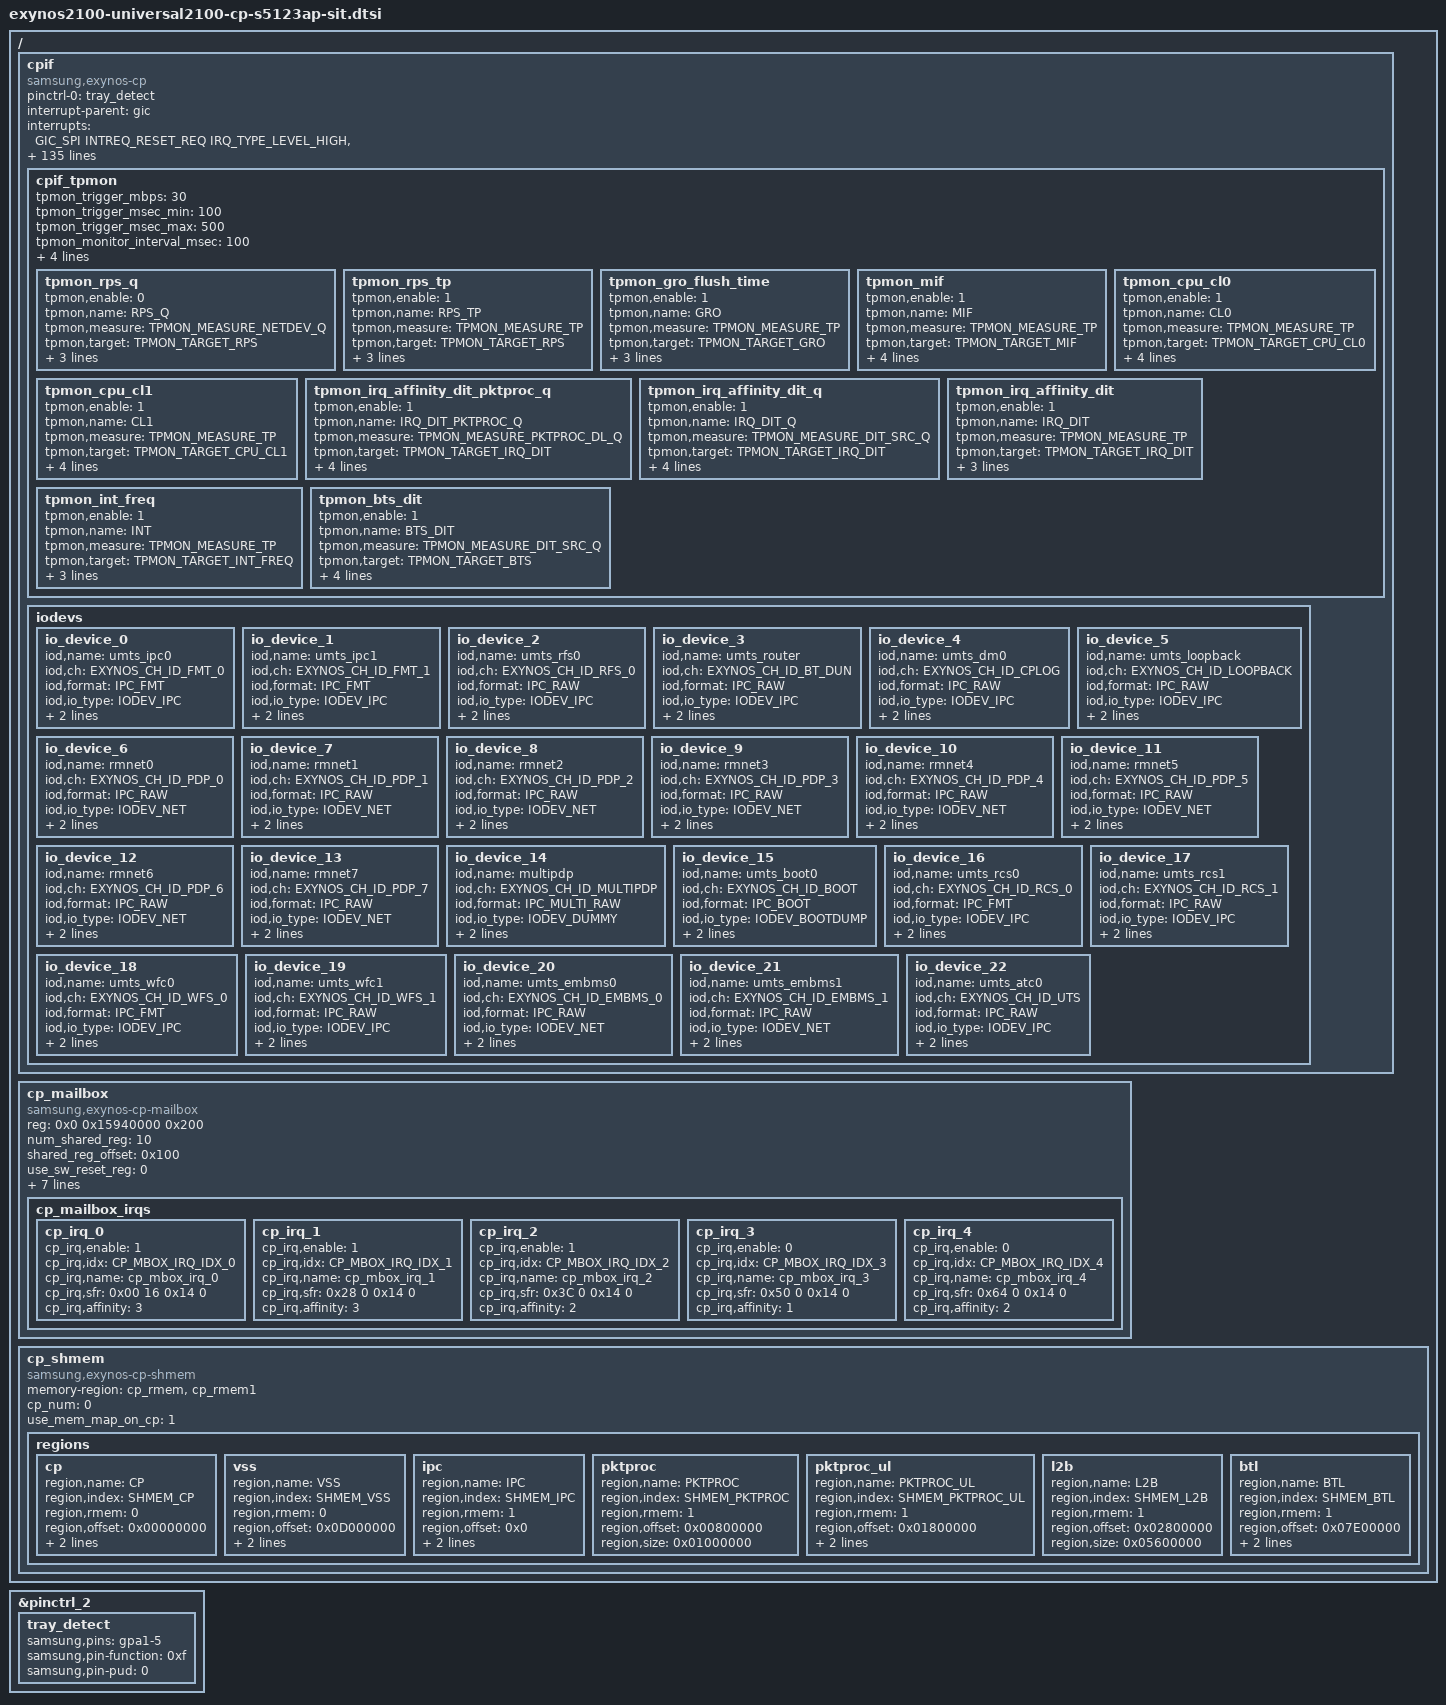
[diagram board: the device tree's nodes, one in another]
// SPDX-License-Identifier: GPL-2.0
/*
 * Samsung CP interface device tree source
 *
 * Copyright (c) 2019-2020 Samsung Electronics Co., Ltd.
 *             http://www.samsung.com
 *
 * This program is free software; you can redistribute it and/or modify
 * it under the terms of the GNU General Public License version 2 as
 * published by the Free Software Foundation.
 */

#include <dt-bindings/soc/samsung/exynos-cpif.h>
#include <dt-bindings/interrupt-controller/exynos2100.h>

/ {
	fragment@modemif {
		target-path = "/";
		__overlay__ {
			#address-cells = <2>;
			#size-cells = <1>;

			/* Modem interface information */
			cpif {
				compatible = "samsung,exynos-cp";
				status = "okay";

				pinctrl-names = "default";
				pinctrl-0 = <&tray_detect>;

				interrupt-parent = <&gic>;
				interrupts = <GIC_SPI INTREQ_RESET_REQ IRQ_TYPE_LEVEL_HIGH>,
						<GIC_SPI SFR_BUS_RDY IRQ_TYPE_LEVEL_HIGH>;
				interrupt-names = "RESET_REQ", "CP_ACTIVE";

				ap2cp_cfg_addr = <0x14020000>;

				/* */
				mif,name = "s5123ap";
				mif,cp_num = <0>;
				mif,modem_type = <SEC_S5000AP>;
				mif,protocol = <PROTOCOL_SIT>;
				mif,ipc_version = <SIPC_VER_50>;
				mif,link_type = <LINKDEV_SHMEM>;
				mif,link_name = "shmem";
				mif,link_attrs = <(LINK_ATTR_XMIT_BTDLR |
							LINK_ATTR_DUMP_ALIGNED | LINK_ATTR_BOOT_ALIGNED |
							LINK_ATTR_MEM_DUMP | LINK_ATTR_MEM_BOOT |
							LINK_ATTR_DPRAM_MAGIC)>;
				mif,interrupt_types = <INTERRUPT_MAILBOX>;
				mif,capability_check = <1>;

				/* Mailbox interrupt number from AP to CP */
				mif,int_ap2cp_msg = <0>;
				mif,int_ap2cp_wakeup = <1>;
				mif,int_ap2cp_status = <2>;
				mif,int_ap2cp_active = <3>;
				mif,int_ap2cp_lcd_status = <4>;
				mif,int_ap2cp_llc_status = <5>;
				mif,int_ap2cp_uart_noti = <15>;

				/* Mailbox interrupt number from CP to AP */
				mif,irq_cp2ap_msg = <0>;
				mif,irq_cp2ap_status = <2>;
				mif,irq_cp2ap_active = <3>;
				mif,irq_cp2ap_wakelock = <8>;
				mif,irq_cp2ap_ratmode = <9>;

				/* Malibox (CP_MBOX_IRQ_IDX_2) interrupt number from CP to AP */
				mif,mbox2_irq_cp2ap_llc_status = <5>;

				/* Legacy Buffers (FMT, RAW) */
				legacy_fmt_head_tail_offset = <0x10>;
				legacy_fmt_buffer_offset = <0x1000>;
				legacy_fmt_txq_size = <0x1000>;
				legacy_fmt_rxq_size = <0x1000>;
				legacy_raw_head_tail_offset = <0x20>;
				legacy_raw_buffer_offset = <0x3000>;
				legacy_raw_txq_size = <0x1FD000>;
				legacy_raw_rxq_size = <0x200000>;

				/*
				 * Legacy Priority Queue
				 * (available only if CONFIG_MODEM_IF_LEGACY_QOS used)
				 */
				legacy_raw_qos_head_tail_offset = <0x30>;
				legacy_raw_qos_buffer_offset = <0x400000>;
				legacy_raw_qos_txq_size = <0x100000>;
				legacy_raw_qos_rxq_size = <0x100000>;

				offset_cmsg_offset = <0x60>;
				offset_srinfo_offset = <0x64>;
				offset_clk_table_offset = <0x68>;
				offset_buff_desc_offset = <0x6C>;
				offset_capability_offset = <0x70>;

				cmsg_offset = <0xC0>;
				srinfo_offset = <0x300>;
				srinfo_size = <0x800>;
				clk_table_offset = <0x200>;
				buff_desc_offset = <0xC00>;
				capability_offset = <0xA0>;

				/* capability value */
				ap_capability_0 = <0x0>;
				ap_capability_1 = <0x0>;

				/*
				 * Control messages containing two elements
				 * <MAILBOX_SR [shared register number]>
				 * <DRAM_V1   [offset from ipc base]>
				 * <DRAM_V2   [offset from cmsg offset]>
				 */
				ap2cp_msg = <DRAM_V2 0x0>;
				cp2ap_msg = <DRAM_V2 0x4>;
				ap2cp_united_status = <DRAM_V2 0x8>;
				cp2ap_united_status = <DRAM_V2 0xC>;
				ap2cp_llc_status = <DRAM_V2 0x10>;
				cp2ap_llc_status = <DRAM_V2 0x14>;
				ap2cp_kerneltime_sec = <DRAM_V2 0x38>;
				ap2cp_kerneltime_usec = <DRAM_V2 0x3C>;

				/* Status bit info for mbx_ap2cp_united_status */
				sbi_lcd_status_mask = <0x1>;
				sbi_lcd_status_pos = <27>;
				sbi_crash_type_mask = <0xf>;
				sbi_crash_type_pos = <23>;
				sbi_ext_backtrace_mask = <0x1>;
				sbi_ext_backtrace_pos = <17>;
				sbi_uart_noti_mask = <0x1>;
				sbi_uart_noti_pos = <16>;
				sbi_ds_det_mask = <0x3>;
				sbi_ds_det_pos = <14>;
				sbi_sys_rev_mask = <0xff>;
				sbi_sys_rev_pos = <6>;
				sbi_pda_active_mask = <0x1>;
				sbi_pda_active_pos = <5>;
				sbi_ap_status_mask = <0xf>;
				sbi_ap_status_pos = <1>;

				/* Status bit info for mbx_cp2ap_united_status */
				sbi_cp_rat_mode_mask = <0x3f>;
				sbi_cp_rat_mode_pos = <26>;
				sbi_cp_evs_mode_mask = <0x1>;
				sbi_cp_evs_mode_pos = <7>;
				sbi_cp2ap_wakelock_mask = <0x1>;
				sbi_cp2ap_wakelock_pos = <6>;
				sbi_lte_active_mask = <0x1>;
				sbi_lte_active_pos = <5>;
				sbi_cp_status_mask = <0xf>;
				sbi_cp_status_pos = <1>;

				/* status bit info for ap2cp_llc_status */
				sbi_ap_llc_return_mask = <0xf>;
				sbi_ap_llc_return_pos = <9>;
				sbi_ap_llc_alloc_mask = <0x1>;
				sbi_ap_llc_alloc_pos = <8>;
				sbi_ap_llc_way_mask = <0xff>;
				sbi_ap_llc_way_pos = <0>;

				/* status bit info for cp2ap_llc_status */
				sbi_cp_llc_return_mask = <0xf>;
				sbi_cp_llc_return_pos = <9>;
				sbi_cp_llc_alloc_mask = <0x1>;
				sbi_cp_llc_alloc_pos = <8>;
				sbi_cp_llc_way_mask = <0xff>;
				sbi_cp_llc_way_pos = <0>;

				/* CP BTL (Back Trace Log) */
				cp_btl_node_name = "ramdump_memshare";

				/* Packet processor */
				pktproc_support = <1>;
				pktproc_version = <2>;

				pktproc_cp_base = <0x50800000>;
				pktproc_info_rgn_offset = <0x00000000>;
				pktproc_info_rgn_size = <0x00000100>;
				pktproc_desc_rgn_offset = <0x00000100>;
				pktproc_desc_rgn_size = <0x000FFF00>;
				pktproc_buff_rgn_offset = <0x00100000>;
				/* Size of data buffer region is defined by reserved mem size */

				pktproc_info_desc_rgn_cached = <0>;
				pktproc_buff_rgn_cached = <0>;

				pktproc_desc_mode = <1>;	/* Descriptor structure mode. 0:ringbuf mode, 1:sktbuf mode */
				pktproc_num_queue = <1>;
				pktproc_use_exclusive_irq = <1>;
				pktproc_exclusive_irq_idx = <CP_MBOX_IRQ_IDX_1 CP_MBOX_IRQ_IDX_2 CP_MBOX_IRQ_IDX_3 CP_MBOX_IRQ_IDX_4>;
				pktproc_use_buff_mng = <0>;
				pktproc_desc_num_ratio_percent = <50>;
				pktproc_use_napi = <1>;
				pktproc_use_hw_iocc = <0>;	/* H/W IO cache coherency */
				pktproc_max_packet_size = <2048>;
				pktproc_use_dedicated_baaw = <1>;
				pktproc_use_36bit_data_addr = <1>;

				/* Packet processor for UL */
				pktproc_support_ul = <1>;
				pktproc_ul_cp_base = <0x51800000>;
				pktproc_ul_info_rgn_offset = <0x00000000>;
				pktproc_ul_info_rgn_size = <0x00000100>;
				pktproc_ul_desc_rgn_offset = <0x00000100>;
				pktproc_ul_desc_rgn_size = <0x000FFF00>;
				pktproc_ul_buff_rgn_offset = <0x00100000>;
				pktproc_ul_padding_required = <1>; /* for s5123 EVT1 only */
				pktproc_ul_num_queue = <2>;
				pktproc_ul_max_packet_size = <2048>;
				pktproc_ul_info_desc_rgn_cached = <0>;
				pktproc_ul_buff_rgn_cached = <0>;
				pktproc_ul_use_hw_iocc = <0>; /* H/W IO cache coherency */

				devfreq_use_dfs_max_freq = <1>;
				devfreq_cal_id_mif = <ACPM_DVFS_MIF>;

				/* TPMON: CP throughput monitor */
				cpif_tpmon {
					tpmon_trigger_mbps = <30>;
					tpmon_trigger_msec_min = <100>;
					tpmon_trigger_msec_max = <500>;

					tpmon_monitor_interval_msec = <100>;
					tpmon_monitor_hold_msec = <3000>;
					tpmon_monitor_stop_mbps = <15>;

					tpmon_boost_hold_msec = <6000>;
					tpmon_unboost_tp_percent = <40>;

					tpmon_rps_q {
						tpmon,enable = <0>;
						tpmon,name = "RPS_Q";
						tpmon,measure = <TPMON_MEASURE_NETDEV_Q>;
						tpmon,target = <TPMON_TARGET_RPS>;
						tpmon,idx = <0>;
						tpmon,threshold = <3000>;	/* Netdev backlog queue */
						tpmon,values = <0x03 0x30>;
					};
					tpmon_rps_tp {
						tpmon,enable = <1>;
						tpmon,name = "RPS_TP";
						tpmon,measure = <TPMON_MEASURE_TP>;
						tpmon,target = <TPMON_TARGET_RPS>;
						tpmon,idx = <0>;
						tpmon,threshold = <300>;	/* Mbps */
						tpmon,values = <0x03 0x30>;
					};
					tpmon_gro_flush_time {
						tpmon,enable = <1>;
						tpmon,name = "GRO";
						tpmon,measure = <TPMON_MEASURE_TP>;
						tpmon,target = <TPMON_TARGET_GRO>;
						tpmon,idx = <0>;
						tpmon,threshold = <100 200>;	/* Mbps */
						tpmon,values = <10000 50000 100000>;
					};
					tpmon_mif {
						tpmon,enable = <1>;
						tpmon,name = "MIF";
						tpmon,measure = <TPMON_MEASURE_TP>;
						tpmon,target = <TPMON_TARGET_MIF>;
						tpmon,idx = <0>;
						tpmon,threshold = <700>;	/* Mbps */
						tpmon,values = <0 1014000>;
						tpmon,check_udp = <1>;
					};
					tpmon_cpu_cl0 {
						tpmon,enable = <1>;
						tpmon,name = "CL0";
						tpmon,measure = <TPMON_MEASURE_TP>;
						tpmon,target = <TPMON_TARGET_CPU_CL0>;
						tpmon,idx = <0>;
						tpmon,threshold = <100 300>;	/* Mbps */
						tpmon,values = <0 1066000 1274000>;
						tpmon,check_udp = <1>;
					};
					tpmon_cpu_cl1 {
						tpmon,enable = <1>;
						tpmon,name = "CL1";
						tpmon,measure = <TPMON_MEASURE_TP>;
						tpmon,target = <TPMON_TARGET_CPU_CL1>;
						tpmon,idx = <4>;
						tpmon,threshold = <500 700 1500>;	/* Mbps */
						tpmon,values = <0 832000 1248000 1560000>;
						tpmon,check_udp = <1>;
					};
					tpmon_irq_affinity_dit_pktproc_q {
						tpmon,enable = <1>;
						tpmon,name = "IRQ_DIT_PKTPROC_Q";
						tpmon,measure = <TPMON_MEASURE_PKTPROC_DL_Q>;
						tpmon,target = <TPMON_TARGET_IRQ_DIT>;
						tpmon,idx = <0>;
						tpmon,threshold = <6000>;	/* PktProc rear~fore usage */
						tpmon,values = <2 6>;
						tpmon,urgent = <1>;
					};
					tpmon_irq_affinity_dit_q {
						tpmon,enable = <1>;
						tpmon,name = "IRQ_DIT_Q";
						tpmon,measure = <TPMON_MEASURE_DIT_SRC_Q>;
						tpmon,target = <TPMON_TARGET_IRQ_DIT>;
						tpmon,idx = <0>;
						tpmon,threshold = <7000>;	/* DIT src queue */
						tpmon,values = <2 6>;
						tpmon,urgent = <1>;
					};
					tpmon_irq_affinity_dit {
						tpmon,enable = <1>;
						tpmon,name = "IRQ_DIT";
						tpmon,measure = <TPMON_MEASURE_TP>;
						tpmon,target = <TPMON_TARGET_IRQ_DIT>;
						tpmon,idx = <0>;
						tpmon,threshold = <1750>;	/* Mbps */
						tpmon,values = <2 6>;
					};
					tpmon_int_freq {
						tpmon,enable = <1>;
						tpmon,name = "INT";
						tpmon,measure = <TPMON_MEASURE_TP>;
						tpmon,target = <TPMON_TARGET_INT_FREQ>;
						tpmon,idx = <0>;
						tpmon,threshold = <1750 2750>;	/* Mbps */
						tpmon,values = <0 400000 533000>;
					};
					tpmon_bts_dit {
						tpmon,enable = <1>;
						tpmon,name = "BTS_DIT";
						tpmon,measure = <TPMON_MEASURE_DIT_SRC_Q>;
						tpmon,target = <TPMON_TARGET_BTS>;
						tpmon,idx = <0>;
						tpmon,threshold = <4000>;	/* DIT src queue */
						tpmon,values = <0 1>;
						tpmon,urgent = <1>;
					};
				}; /* end of cpif_tpmon */

				/* IO devices */
				iodevs {
					io_device_0 {
						iod,name = "umts_ipc0";
						iod,ch = <EXYNOS_CH_ID_FMT_0>;
						iod,format = <IPC_FMT>;
						iod,io_type = <IODEV_IPC>;
						iod,link_type = <LINKDEV_SHMEM>;
						iod,attrs = <(0x0)>;
					};
					io_device_1 {
						iod,name = "umts_ipc1";
						iod,ch = <EXYNOS_CH_ID_FMT_1>;
						iod,format = <IPC_FMT>;
						iod,io_type = <IODEV_IPC>;
						iod,link_type = <LINKDEV_SHMEM>;
						iod,attrs = <(0x0)>;
					};
					io_device_2 {
						iod,name = "umts_rfs0";
						iod,ch = <EXYNOS_CH_ID_RFS_0>;
						iod,format = <IPC_RAW>;
						iod,io_type = <IODEV_IPC>;
						iod,link_type = <LINKDEV_SHMEM>;
						iod,attrs = <(0x0)>;
					};
					io_device_3 {
						iod,name = "umts_router";
						iod,ch = <EXYNOS_CH_ID_BT_DUN>;
						iod,format = <IPC_RAW>;
						iod,io_type = <IODEV_IPC>;
						iod,link_type = <LINKDEV_SHMEM>;
						iod,attrs = <(0x0)>;
					};
					io_device_4 {
						iod,name = "umts_dm0";
						iod,ch = <EXYNOS_CH_ID_CPLOG>;
						iod,format = <IPC_RAW>;
						iod,io_type = <IODEV_IPC>;
						iod,link_type = <LINKDEV_SHMEM>;
						iod,attrs = <(0x0)>;
					};
					io_device_5 {
						iod,name = "umts_loopback";
						iod,ch = <EXYNOS_CH_ID_LOOPBACK>;
						iod,format = <IPC_RAW>;
						iod,io_type = <IODEV_IPC>;
						iod,link_type = <LINKDEV_SHMEM>;
						iod,attrs = <(0x0)>;
					};
					io_device_6 {
						iod,name = "rmnet0";
						iod,ch = <EXYNOS_CH_ID_PDP_0>;
						iod,format = <IPC_RAW>;
						iod,io_type = <IODEV_NET>;
						iod,link_type = <LINKDEV_SHMEM>;
						iod,attrs = <(0x0)>;
					};
					io_device_7 {
						iod,name = "rmnet1";
						iod,ch = <EXYNOS_CH_ID_PDP_1>;
						iod,format = <IPC_RAW>;
						iod,io_type = <IODEV_NET>;
						iod,link_type = <LINKDEV_SHMEM>;
						iod,attrs = <(0x0)>;
					};
					io_device_8 {
						iod,name = "rmnet2";
						iod,ch = <EXYNOS_CH_ID_PDP_2>;
						iod,format = <IPC_RAW>;
						iod,io_type = <IODEV_NET>;
						iod,link_type = <LINKDEV_SHMEM>;
						iod,attrs = <(0x0)>;
					};
					io_device_9 {
						iod,name = "rmnet3";
						iod,ch = <EXYNOS_CH_ID_PDP_3>;
						iod,format = <IPC_RAW>;
						iod,io_type = <IODEV_NET>;
						iod,link_type = <LINKDEV_SHMEM>;
						iod,attrs = <(0x0)>;
					};
					io_device_10 {
						iod,name = "rmnet4";
						iod,ch = <EXYNOS_CH_ID_PDP_4>;
						iod,format = <IPC_RAW>;
						iod,io_type = <IODEV_NET>;
						iod,link_type = <LINKDEV_SHMEM>;
						iod,attrs = <(0x0)>;
					};
					io_device_11 {
						iod,name = "rmnet5";
						iod,ch = <EXYNOS_CH_ID_PDP_5>;
						iod,format = <IPC_RAW>;
						iod,io_type = <IODEV_NET>;
						iod,link_type = <LINKDEV_SHMEM>;
						iod,attrs = <(0x0)>;
					};
					io_device_12 {
						iod,name = "rmnet6";
						iod,ch = <EXYNOS_CH_ID_PDP_6>;
						iod,format = <IPC_RAW>;
						iod,io_type = <IODEV_NET>;
						iod,link_type = <LINKDEV_SHMEM>;
						iod,attrs = <(0x0)>;
					};
					io_device_13 {
						iod,name = "rmnet7";
						iod,ch = <EXYNOS_CH_ID_PDP_7>;
						iod,format = <IPC_RAW>;
						iod,io_type = <IODEV_NET>;
						iod,link_type = <LINKDEV_SHMEM>;
						iod,attrs = <(0x0)>;
					};
					io_device_14 {
						iod,name = "multipdp";
						iod,ch = <EXYNOS_CH_ID_MULTIPDP>;
						iod,format = <IPC_MULTI_RAW>;
						iod,io_type = <IODEV_DUMMY>;
						iod,link_type = <LINKDEV_SHMEM>;
						iod,attrs = <(0x0)>;
					};
					io_device_15 {
						iod,name = "umts_boot0";
						iod,ch = <EXYNOS_CH_ID_BOOT>;
						iod,format = <IPC_BOOT>;
						iod,io_type = <IODEV_BOOTDUMP>;
						iod,link_type = <LINKDEV_SHMEM>;
						iod,attrs = <(IO_ATTR_NO_CHECK_MAXQ)>;
					};
					io_device_16 {
						iod,name = "umts_rcs0";
						iod,ch = <EXYNOS_CH_ID_RCS_0>;
						iod,format = <IPC_FMT>;
						iod,io_type = <IODEV_IPC>;
						iod,link_type = <LINKDEV_SHMEM>;
						iod,attrs = <(0x0)>;
					};
					io_device_17 {
						iod,name = "umts_rcs1";
						iod,ch = <EXYNOS_CH_ID_RCS_1>;
						iod,format = <IPC_RAW>;
						iod,io_type = <IODEV_IPC>;
						iod,link_type = <LINKDEV_SHMEM>;
						iod,attrs = <(0x0)>;
					};
					io_device_18 {
						iod,name = "umts_wfc0";
						iod,ch = <EXYNOS_CH_ID_WFS_0>;
						iod,format = <IPC_FMT>;
						iod,io_type = <IODEV_IPC>;
						iod,link_type = <LINKDEV_SHMEM>;
						iod,attrs = <(0x0)>;
					};
					io_device_19 {
						iod,name = "umts_wfc1";
						iod,ch = <EXYNOS_CH_ID_WFS_1>;
						iod,format = <IPC_RAW>;
						iod,io_type = <IODEV_IPC>;
						iod,link_type = <LINKDEV_SHMEM>;
						iod,attrs = <(0x0)>;
					};
					io_device_20 {
						iod,name = "umts_embms0";
						iod,ch = <EXYNOS_CH_ID_EMBMS_0>;
						iod,format = <IPC_RAW>;
						iod,io_type = <IODEV_NET>;
						iod,link_type = <LINKDEV_SHMEM>;
						iod,attrs = <(0x0)>;
					};
					io_device_21 {
						iod,name = "umts_embms1";
						iod,ch = <EXYNOS_CH_ID_EMBMS_1>;
						iod,format = <IPC_RAW>;
						iod,io_type = <IODEV_NET>;
						iod,link_type = <LINKDEV_SHMEM>;
						iod,attrs = <(0x0)>;
					};
					io_device_22 {
						iod,name = "umts_atc0";
						iod,ch = <EXYNOS_CH_ID_UTS>;
						iod,format = <IPC_RAW>;
						iod,io_type = <IODEV_IPC>;
						iod,link_type = <LINKDEV_SHMEM>;
						iod,attrs = <(0x0)>;
					};
				}; /* end of iodevs */
			}; /* end of cpif */

			/* Mailbox information */
			cp_mailbox {
				compatible = "samsung,exynos-cp-mailbox";

				reg = <0x0 0x15940000 0x200>;

				num_shared_reg = <10>;
				shared_reg_offset = <0x100>;
				use_sw_reset_reg = <0>;

				interrupt-parent = <&gic>;
				interrupts = <GIC_SPI INTREQ__MAILBOX_CP2AP_0 IRQ_TYPE_LEVEL_HIGH>,
						<GIC_SPI INTREQ__MAILBOX_CP2AP_1 IRQ_TYPE_LEVEL_HIGH>,
						<GIC_SPI INTREQ__MAILBOX_CP2AP_2 IRQ_TYPE_LEVEL_HIGH>,
						<GIC_SPI INTREQ__MAILBOX_CP2AP_3 IRQ_TYPE_LEVEL_HIGH>,
						<GIC_SPI INTREQ__MAILBOX_CP2AP_4 IRQ_TYPE_LEVEL_HIGH>;

				cp_mailbox_irqs {
					/*
					 * irq,sfr = <RX_OFFSET RX_SHIFT TX_OFFSET TX_SHIFT>
					 *     RX_OFFSET: INTGR of RX interrupt offset from INTGR0
					 *     RX_SHIFT: Set a value when SFR is not started from bit 0
					 *     TX_OFFSET: INTGR of TX interrupt offset from INTGR0
					 *     TX_SHIFT: Set a value when SFR is not started from bit 0
					 */
					cp_irq_0 {
						cp_irq,enable = <1>;
						cp_irq,idx = <CP_MBOX_IRQ_IDX_0>;
						cp_irq,name = "cp_mbox_irq_0";
						cp_irq,sfr = <0x00 16 0x14 0>;
						cp_irq,affinity = <3>;
					};
					cp_irq_1 {
						cp_irq,enable = <1>;
						cp_irq,idx = <CP_MBOX_IRQ_IDX_1>;
						cp_irq,name = "cp_mbox_irq_1";
						cp_irq,sfr = <0x28 0 0x14 0>;
						cp_irq,affinity = <3>;
					};
					cp_irq_2 {
						cp_irq,enable = <1>;
						cp_irq,idx = <CP_MBOX_IRQ_IDX_2>;
						cp_irq,name = "cp_mbox_irq_2";
						cp_irq,sfr = <0x3C 0 0x14 0>;
						cp_irq,affinity = <2>;
					};
					cp_irq_3 {
						cp_irq,enable = <0>;
						cp_irq,idx = <CP_MBOX_IRQ_IDX_3>;
						cp_irq,name = "cp_mbox_irq_3";
						cp_irq,sfr = <0x50 0 0x14 0>;
						cp_irq,affinity = <1>;
					};
					cp_irq_4 {
						cp_irq,enable = <0>;
						cp_irq,idx = <CP_MBOX_IRQ_IDX_4>;
						cp_irq,name = "cp_mbox_irq_4";
						cp_irq,sfr = <0x64 0 0x14 0>;
						cp_irq,affinity = <2>;
					};
				};
			};

			/* Shared memory information*/
			cp_shmem {
				compatible = "samsung,exynos-cp-shmem";

				memory-region = <&cp_rmem>, <&cp_rmem1>;

				cp_num = <0>;
				use_mem_map_on_cp = <1>;

				regions {
					cp {
						region,name = "CP";
						region,index = <SHMEM_CP>;
						region,rmem = <0>;
						region,offset = <0x00000000>;
						region,size = <0x0D000000>;
						region,cached = <0>;
					};
					vss {
						region,name = "VSS";
						region,index = <SHMEM_VSS>;
						region,rmem = <0>;
						region,offset = <0x0D000000>;
						region,size = <0x00800000>;
						region,cached = <0>;
					};
					ipc {
						region,name = "IPC";
						region,index = <SHMEM_IPC>;
						region,rmem = <1>;
						region,offset = <0x0>;
						region,size = <0x00800000>;
						region,cached = <0>;
					};
					pktproc {
						region,name = "PKTPROC";
						region,index = <SHMEM_PKTPROC>;
						region,rmem = <1>;
						region,offset = <0x00800000>;
						region,size = <0x01000000>;
						/* Cached information is defined by pktproc itself */
					};
					pktproc_ul {
						region,name = "PKTPROC_UL";
						region,index = <SHMEM_PKTPROC_UL>;
						region,rmem = <1>;
						region,offset = <0x01800000>;
						region,size = <0x01000000>;
						region,cached = <0>;
					};
					l2b {
						region,name = "L2B";
						region,index = <SHMEM_L2B>;
						region,rmem = <1>;
						region,offset = <0x02800000>;
						region,size = <0x05600000>;
					};
					btl {
						region,name = "BTL";
						region,index = <SHMEM_BTL>;
						region,rmem = <1>;
						region,offset = <0x07E00000>;
						region,size = <0x02000000>;
						region,cached = <0>;
					};
				};
			}; /* end of cp_shmem */
		}; /* end of __overlay__ */
	}; /* end of fragment */
}; /* end of root */

&pinctrl_2 {
	tray_detect: tray_detect {
		samsung,pins = "gpa1-5";
		samsung,pin-function = <0xf>;
		samsung,pin-pud = <0>;
	};
};
